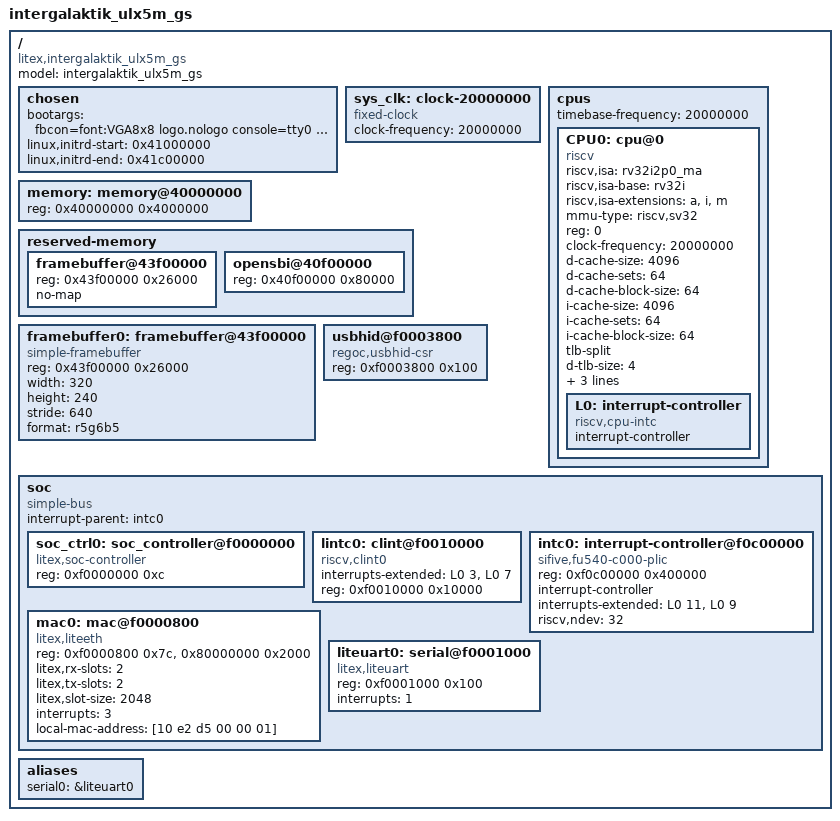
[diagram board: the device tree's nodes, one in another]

/dts-v1/;

/ {
        compatible = "litex,intergalaktik_ulx5m_gs", "litex,soc";
        model = "intergalaktik_ulx5m_gs";
        #address-cells = <1>;
        #size-cells    = <1>;


        chosen {
            bootargs = "fbcon=font:VGA8x8 logo.nologo console=tty0 console=liteuart earlycon=liteuart,0xf0001000 rootwait root=/dev/ram0 ip=192.168.10.213:192.168.10.14:192.168.10.14:255.255.255.0::eth0:off:::";
            linux,initrd-start = <0x41000000>;
            linux,initrd-end   = <0x41c00000>;
        };

        sys_clk: clock-20000000 {
            compatible = "fixed-clock";
            #clock-cells = <0>;
            clock-frequency  = <20000000>;
        };

        cpus {
            #address-cells = <1>;
            #size-cells    = <0>;
            timebase-frequency = <20000000>;

            CPU0: cpu@0 {
                device_type = "cpu";
                compatible = "riscv";
                riscv,isa = "rv32i2p0_ma";
                riscv,isa-base = "rv32i";
                riscv,isa-extensions = "a", "i", "m";
                mmu-type = "riscv,sv32";
                reg = <0>;
                clock-frequency = <20000000>;
                status = "okay";
                
                d-cache-size = <4096>;
                d-cache-sets = <64>;
                d-cache-block-size = <64>;

                i-cache-size = <4096>;
                i-cache-sets = <64>;
                i-cache-block-size = <64>;

                
                tlb-split;
                d-tlb-size = <4>;
                d-tlb-sets = <4>;

                i-tlb-size = <4>;
                i-tlb-sets = <4>;

                
                L0: interrupt-controller {
                    #address-cells = <0>;
                    #interrupt-cells = <0x00000001>;
                    interrupt-controller;
                    compatible = "riscv,cpu-intc";
                };
            };

            
            
        };

        memory: memory@40000000 {
            device_type = "memory";
            reg = <0x40000000 0x4000000>;
        };

        reserved-memory {
            #address-cells = <1>;
            #size-cells    = <1>;
            ranges;

            framebuffer@43f00000 {
                reg = <0x43f00000 0x26000>;
                no-map;
            };

            opensbi@40f00000 {
                reg = <0x40f00000 0x80000>;
            };

        };

        framebuffer0: framebuffer@43f00000 {
            compatible = "simple-framebuffer";
            reg = <0x43f00000 0x26000>;
            width = <320>;
            height = <240>;
            stride = <640>;
            format = "r5g6b5";
            status = "okay";
        };

        usbhid@f0003800 {
            compatible = "regoc,usbhid-csr";
            reg = <0xf0003800 0x100>;
            status = "okay";
        };

        soc {
            #address-cells = <1>;
            #size-cells    = <1>;
            compatible = "simple-bus";
            interrupt-parent = <&intc0>;
            ranges;

            soc_ctrl0: soc_controller@f0000000 {
                compatible = "litex,soc-controller";
                reg = <0xf0000000 0xc>;
                status = "okay";
            };

            lintc0: clint@f0010000 {
                compatible = "riscv,clint0";
                interrupts-extended = <
                    &L0 3 &L0 7>;
                reg = <0xf0010000 0x10000>;
                reg-names = "control";
            };

            intc0: interrupt-controller@f0c00000 {
                compatible = "sifive,fu540-c000-plic", "sifive,plic-1.0.0";
                reg = <0xf0c00000 0x400000>;
                #address-cells = <0>;
                #interrupt-cells = <1>;
                interrupt-controller;
                interrupts-extended = <
                    &L0 11 &L0 9>;
                riscv,ndev = <32>;
                
            };

            mac0: mac@f0000800 {
                compatible = "litex,liteeth";
                reg = <0xf0000800 0x7c>, <0x80000000 0x2000>;
                reg-names = "mac", "buffer";
                litex,rx-slots = <2>;
                litex,tx-slots = <2>;
                litex,slot-size = <2048>;
                interrupts = <3>;
                local-mac-address = [10 e2 d5 00 00 01];
                status = "okay";
            };

            liteuart0: serial@f0001000 {
                compatible = "litex,liteuart";
                reg = <0xf0001000 0x100>;
                interrupts = <1>;
                status = "okay";
            };

        };

        aliases {

                serial0 = &liteuart0;

        };

};

